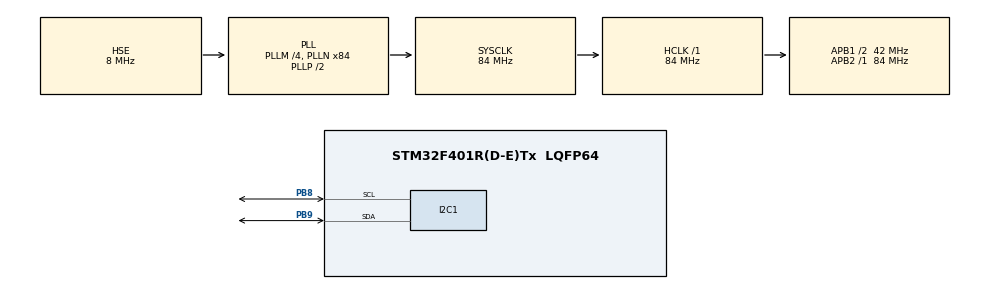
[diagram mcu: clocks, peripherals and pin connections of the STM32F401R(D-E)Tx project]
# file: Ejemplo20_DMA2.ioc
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Dma.I2C1_TX.0.Direction=DMA_MEMORY_TO_PERIPH
Dma.I2C1_TX.0.FIFOMode=DMA_FIFOMODE_ENABLE
Dma.I2C1_TX.0.FIFOThreshold=DMA_FIFO_THRESHOLD_FULL
Dma.I2C1_TX.0.Instance=DMA1_Stream6
Dma.I2C1_TX.0.MemBurst=DMA_MBURST_SINGLE
Dma.I2C1_TX.0.MemDataAlignment=DMA_MDATAALIGN_BYTE
Dma.I2C1_TX.0.MemInc=DMA_MINC_ENABLE
Dma.I2C1_TX.0.Mode=DMA_CIRCULAR
Dma.I2C1_TX.0.PeriphBurst=DMA_PBURST_SINGLE
Dma.I2C1_TX.0.PeriphDataAlignment=DMA_PDATAALIGN_BYTE
Dma.I2C1_TX.0.PeriphInc=DMA_PINC_DISABLE
Dma.I2C1_TX.0.Priority=DMA_PRIORITY_LOW
Dma.Request0=I2C1_TX
Mcu.Family=STM32F4
Mcu.Name=STM32F401R(D-E)Tx
Mcu.Package=LQFP64
NVIC.DMA1_Stream6_IRQn=true\:0\:0\:false\:false\:true\:false\:true\:true
NVIC.I2C1_EV_IRQn=true\:0\:0\:false\:false\:true\:true\:true\:true
NVIC.PriorityGroup=NVIC_PRIORITYGROUP_4
PA13.Mode=Serial_Wire
PA13.Signal=SYS_JTMS-SWDIO
PA14.Mode=Serial_Wire
PA14.Signal=SYS_JTCK-SWCLK
PB8.Mode=I2C
PB8.Signal=I2C1_SCL
PB9.Mode=I2C
PB9.Signal=I2C1_SDA
PH0\ -\ OSC_IN.Mode=HSE-External-Clock-Source
PH0\ -\ OSC_IN.Signal=RCC_OSC_IN
PH1\ -\ OSC_OUT.Mode=HSE-External-Clock-Source
PH1\ -\ OSC_OUT.Signal=RCC_OSC_OUT
ProjectManager.HeapSize=0x200
ProjectManager.StackSize=0x400
ProjectManager.TargetToolchain=STM32CubeIDE
RCC.48MHZClocksFreq_Value=42000000
RCC.AHBFreq_Value=84000000
RCC.APB1CLKDivider=RCC_HCLK_DIV2
RCC.APB1Freq_Value=42000000
RCC.APB1TimFreq_Value=84000000
RCC.APB2Freq_Value=84000000
RCC.APB2TimFreq_Value=84000000
RCC.CortexFreq_Value=84000000
RCC.HCLKFreq_Value=84000000
RCC.HSE_VALUE=8000000
RCC.HSI_VALUE=16000000
RCC.LSE_VALUE=32768
RCC.PLLM=4
RCC.PLLN=84
RCC.PLLSourceVirtual=RCC_PLLSOURCE_HSE
RCC.SYSCLKFreq_VALUE=84000000
RCC.SYSCLKSource=RCC_SYSCLKSOURCE_PLLCLK
RCC.VCOOutputFreq_Value=168000000
board=custom

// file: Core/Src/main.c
/* USER CODE BEGIN Header */
/**
  ******************************************************************************
  * @file           : main.c
  * @brief          : Main program body
  ******************************************************************************
  * @attention
  *
  * Copyright (c) 2023 STMicroelectronics.
  * All rights reserved.
  *
  * This software is licensed under terms that can be found in the LICENSE file
  * in the root directory of this software component.
  * If no LICENSE file comes with this software, it is provided AS-IS.
  *
  ******************************************************************************
  */
/* USER CODE END Header */
#include "main.h"
#include "dma.h"
#include "i2c.h"
#include "gpio.h"

/* USER CODE BEGIN Includes */
#include "LCD.h"
/* USER CODE END Includes */

void SystemClock_Config(void);

int main(void)
{

  /* MCU Configuration--------------------------------------------------------*/

  /* Reset of all peripherals, Initializes the Flash interface and the Systick. */
  HAL_Init();

  /* Configure the system clock */
  SystemClock_Config();

  /* Initialize all configured peripherals */
  MX_GPIO_Init();
  MX_DMA_Init();
  MX_I2C1_Init();
  /* USER CODE BEGIN 2 */

  LCD_STM32_INIT();

  LCD_STM32_SET_CURSOR(0, fila1);
  LCD_STM32_PRINT_STRING("LCD CON DMA");
  uint8_t count  = 0;
  char str_count[15];
  /* USER CODE END 2 */

  /* Infinite loop */
  /* USER CODE BEGIN WHILE */
  while (1)
  {
	  for (count = 0; count < 256; ++count) {
			  LCD_STM32_SET_CURSOR(0, fila2);
			  sprintf(str_count,"C:%03u",count);
			  LCD_STM32_PRINT_STRING(str_count);
			  HAL_Delay(300);
		  }
    /* USER CODE END WHILE */

  }
}

void SystemClock_Config(void)
{
  RCC_OscInitTypeDef RCC_OscInitStruct = {0};
  RCC_ClkInitTypeDef RCC_ClkInitStruct = {0};

  /** Configure the main internal regulator output voltage
  */
  __HAL_RCC_PWR_CLK_ENABLE();
  __HAL_PWR_VOLTAGESCALING_CONFIG(PWR_REGULATOR_VOLTAGE_SCALE2);

  /** Initializes the RCC Oscillators according to the specified parameters
  * in the RCC_OscInitTypeDef structure.
  */
  RCC_OscInitStruct.OscillatorType = RCC_OSCILLATORTYPE_HSE;
  RCC_OscInitStruct.HSEState = RCC_HSE_BYPASS;
  RCC_OscInitStruct.PLL.PLLState = RCC_PLL_ON;
  RCC_OscInitStruct.PLL.PLLSource = RCC_PLLSOURCE_HSE;
  RCC_OscInitStruct.PLL.PLLM = 4;
  RCC_OscInitStruct.PLL.PLLN = 84;
  RCC_OscInitStruct.PLL.PLLP = RCC_PLLP_DIV2;
  RCC_OscInitStruct.PLL.PLLQ = 4;
  if (HAL_RCC_OscConfig(&RCC_OscInitStruct) != HAL_OK)
  {
    Error_Handler();
  }

  /** Initializes the CPU, AHB and APB buses clocks
  */
  RCC_ClkInitStruct.ClockType = RCC_CLOCKTYPE_HCLK|RCC_CLOCKTYPE_SYSCLK
                              |RCC_CLOCKTYPE_PCLK1|RCC_CLOCKTYPE_PCLK2;
  RCC_ClkInitStruct.SYSCLKSource = RCC_SYSCLKSOURCE_PLLCLK;
  RCC_ClkInitStruct.AHBCLKDivider = RCC_SYSCLK_DIV1;
  RCC_ClkInitStruct.APB1CLKDivider = RCC_HCLK_DIV2;
  RCC_ClkInitStruct.APB2CLKDivider = RCC_HCLK_DIV1;

  if (HAL_RCC_ClockConfig(&RCC_ClkInitStruct, FLASH_LATENCY_2) != HAL_OK)
  {
    Error_Handler();
  }
}

void Error_Handler(void)
{
  __disable_irq();
  while (1)
  {
  }
}
